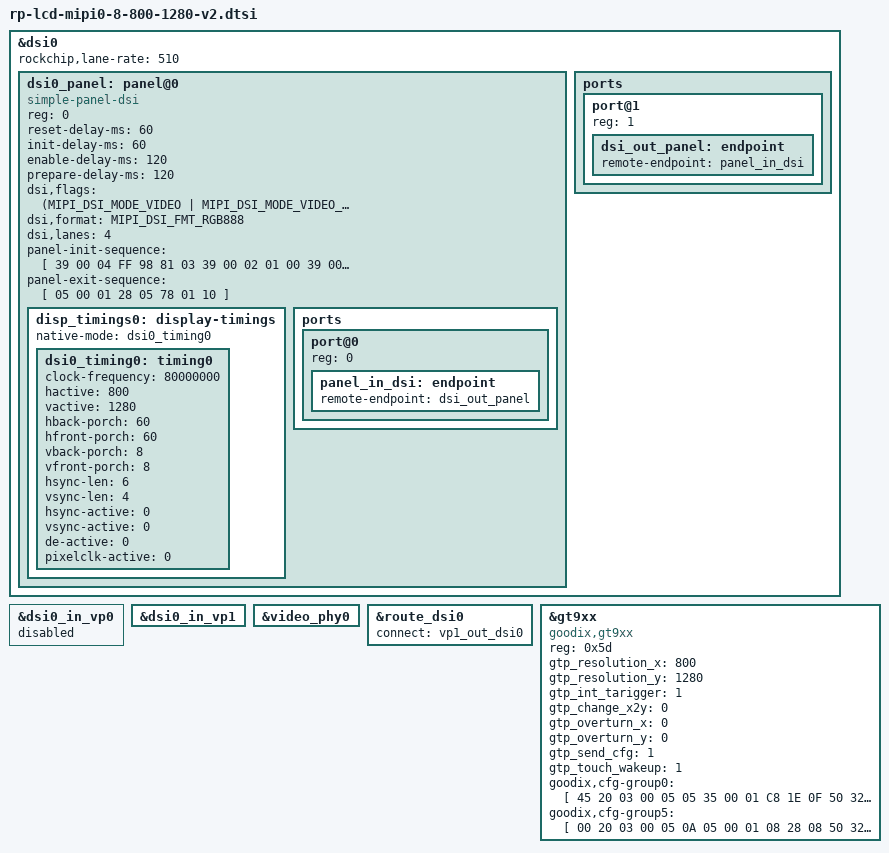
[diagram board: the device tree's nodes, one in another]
#include "rp-lcd-hdmi.dtsi"
#define RP_SINGLE_LCD





&dsi0 {
	status = "okay";
	rockchip,lane-rate = <510>;
	dsi0_panel: panel@0 {
		status = "okay";
		compatible = "simple-panel-dsi";
		reg = <0>;
                reset-delay-ms = <60>;
                init-delay-ms = <60>;
                enable-delay-ms = <120>;
                prepare-delay-ms = <120>;
                dsi,flags = <(MIPI_DSI_MODE_VIDEO | MIPI_DSI_MODE_VIDEO_BURST |
                                MIPI_DSI_MODE_LPM | MIPI_DSI_MODE_EOT_PACKET)>;
		dsi,format = <MIPI_DSI_FMT_RGB888>;
		dsi,lanes  = <4>;
		
		/**
		 * power-supply = <>;
		 * reset-gpios = <>;
		 *
		 * lcd reset pin and power supply
		 * please refer to ***-lcd-gpio.dtsi
		 * that included in main dts.
		 */
		
		panel-init-sequence = [
			39 00 04 FF 98 81 03
			39 00 02 01 00
			39 00 02 02 00
			39 00 02 03 73
			39 00 02 04 D7
			39 00 02 05 00
			39 00 02 06 08
			39 00 02 07 11
			39 00 02 08 00
			39 00 02 09 3F
			39 00 02 0a 00
			39 00 02 0b 00
			39 00 02 0c 00
			39 00 02 0d 00
			39 00 02 0e 00
			39 00 02 0f 3F
			39 00 02 10 3F
			39 00 02 11 00
			39 00 02 12 00
			39 00 02 13 00
			39 00 02 14 00
			39 00 02 15 00
			39 00 02 16 00
			39 00 02 17 00
			39 00 02 18 00
			39 00 02 19 00
			39 00 02 1a 00
			39 00 02 1b 00
			39 00 02 1c 00
			39 00 02 1d 00
			39 00 02 1e 40
			39 00 02 1f 80
			39 00 02 20 06
			39 00 02 21 01
			39 00 02 22 00
			39 00 02 23 00
			39 00 02 24 00
			39 00 02 25 00
			39 00 02 26 00
			39 00 02 27 00
			39 00 02 28 33
			39 00 02 29 33
			39 00 02 2a 00
			39 00 02 2b 00
			39 00 02 2c 00
			39 00 02 2d 00
			39 00 02 2e 00
			39 00 02 2f 00
			39 00 02 30 00
			39 00 02 31 00
			39 00 02 32 00
			39 00 02 33 00
			39 00 02 34 00
			39 00 02 35 00
			39 00 02 36 00
			39 00 02 37 00
			39 00 02 38 00
			39 00 02 39 00
			39 00 02 3a 00
			39 00 02 3b 00
			39 00 02 3c 00
			39 00 02 3d 00
			39 00 02 3e 00
			39 00 02 3f 00
			39 00 02 40 00
			39 00 02 41 00
			39 00 02 42 00
			39 00 02 43 00
			39 00 02 44 00
			39 00 02 50 01
			39 00 02 51 23
			39 00 02 52 44
			39 00 02 53 67
			39 00 02 54 89
			39 00 02 55 ab
			39 00 02 56 01
			39 00 02 57 23
			39 00 02 58 45
			39 00 02 59 67
			39 00 02 5a 89
			39 00 02 5b ab
			39 00 02 5c cd
			39 00 02 5d ef
			39 00 02 5e 00
			39 00 02 5f 0C
			39 00 02 60 0C
			39 00 02 61 0F
			39 00 02 62 0F
			39 00 02 63 0E
			39 00 02 64 0E
			39 00 02 65 06
			39 00 02 66 07
			39 00 02 67 0D
			39 00 02 68 02
			39 00 02 69 02
			39 00 02 6a 02
			39 00 02 6b 02
			39 00 02 6c 02
			39 00 02 6d 02
			39 00 02 6e 0D
			39 00 02 6f 02
			39 00 02 70 02
			39 00 02 71 05
			39 00 02 72 01
			39 00 02 73 08
			39 00 02 74 00
			39 00 02 75 0C
			39 00 02 76 0C
			39 00 02 77 0F
			39 00 02 78 0F
			39 00 02 79 0E
			39 00 02 7a 0E
			39 00 02 7b 06
			39 00 02 7c 07
			39 00 02 7d 0D
			39 00 02 7e 02
			39 00 02 7f 02
			39 00 02 80 02
			39 00 02 81 02
			39 00 02 82 02
			39 00 02 83 02
			39 00 02 84 0D
			39 00 02 85 02
			39 00 02 86 02
			39 00 02 87 05
			39 00 02 88 01
			39 00 02 89 08
			39 00 02 8A 00
			
			39 00 04 FF 98 81 04
			39 00 02 6E 3B
			39 00 02 6F 57
			39 00 02 3A 24
			39 00 02 8D 1F
			39 00 02 87 BA
			39 00 02 B2 D1
			39 00 02 88 0B
			39 00 02 38 01
			39 00 02 39 00
			39 00 02 B5 07
			39 00 02 31 75
			39 00 02 3B 98
			
			39 00 04 FF 98 81 01
			39 00 02 22 0A
			39 00 02 31 09
			39 00 02 35 07
			39 00 02 53 7B
			39 00 02 55 40
			39 00 02 50 86
			39 00 02 51 82
			39 00 02 60 27
			39 00 02 62 20
			39 00 02 A0 00
			39 00 02 A1 12
			39 00 02 A2 20
			39 00 02 A3 13
			39 00 02 A4 14
			39 00 02 A5 27
			39 00 02 A6 1D
			39 00 02 A7 1F
			39 00 02 A8 7C
			39 00 02 A9 1D
			39 00 02 AA 2A
			39 00 02 AB 6B
			39 00 02 AC 1A
			39 00 02 AD 18
			39 00 02 AE 4E
			39 00 02 AF 24
			39 00 02 B0 2A
			39 00 02 B1 4D
			39 00 02 B2 5B
			39 00 02 B3 23
			39 00 02 C0 00
			39 00 02 C1 13
			39 00 02 C2 20
			39 00 02 C3 12
			39 00 02 C4 15
			39 00 02 C5 28
			39 00 02 C6 1C
			39 00 02 C7 1E
			39 00 02 C8 7B
			39 00 02 C9 1E
			39 00 02 CA 29
			39 00 02 CB 6C
			39 00 02 CC 1A
			39 00 02 CD 19
			39 00 02 CE 4D
			39 00 02 CF 22
			39 00 02 D0 2A
			39 00 02 D1 4D
			39 00 02 D2 5B
			39 00 02 D3 23		
			39 00 04 FF 98 81 00
			
			05 78 01 11
			05 78 01 29
		];
		
		panel-exit-sequence = [
			05 00 01 28
			05 78 01 10
		];

		disp_timings0: display-timings {
			native-mode = <&dsi0_timing0>;
			dsi0_timing0: timing0 {
				clock-frequency = <80000000>;
                                hactive = <800>;
                                vactive = <1280>;
                                hback-porch = <60>;
                                hfront-porch = <60>;
                                vback-porch = <8>;
                                vfront-porch = <8>;
                                hsync-len = <6>;
                                vsync-len = <4>;
                                hsync-active = <0>;
                                vsync-active = <0>;
                                de-active = <0>;
                                pixelclk-active = <0>;
			};
		};

		ports {
			#address-cells = <1>;
			#size-cells = <0>;

			port@0 {
				reg = <0>;
				panel_in_dsi: endpoint {
					remote-endpoint = <&dsi_out_panel>;
				};
			};
		};
	};

	ports {
		#address-cells = <1>;
		#size-cells = <0>;

		port@1 {
			reg = <1>;
			dsi_out_panel: endpoint {
				remote-endpoint = <&panel_in_dsi>;
			};
		};
	};

};




&dsi0_in_vp0 {
	status = "disabled";
};

&dsi0_in_vp1 {
	status = "okay";
};



&video_phy0 {
	status = "okay";
};


&route_dsi0 {
	status = "okay";
	connect = <&vp1_out_dsi0>;
};



&gt9xx {
	status = "okay";
	compatible = "goodix,gt9xx";
	reg = <0x5d>;
	gtp_resolution_x = <800>;
	gtp_resolution_y = <1280>;
	gtp_int_tarigger = <1>;
	gtp_change_x2y = <0>;
	gtp_overturn_x = <0>;
	gtp_overturn_y = <0>;
	gtp_send_cfg = <1>;
	gtp_touch_wakeup = <1>;

	/**
	 * goodix_rst_gpio = <>;
	 * goodix_irq_gpio = <>;
	 *
	 * touch panel interrupt and reset pin
	 * please refer to ***-lcd-gpio.dtsi
	 * that included in main dts.
	 */

	goodix,cfg-group0 = [
		45 20 03 00 05 05 35 00 01 C8 
		1E 0F 50 32 03 05 00 00 00 00 
		00 00 04 18 1A 1E 14 8C 2E 0E 
		1E 20 EB 04 00 00 00 BA 02 2D 
		00 00 00 00 00 03 00 00 00 00 
		00 0F 2D 94 D5 02 07 00 00 04 
		E6 10 00 BB 14 00 92 1A 00 78 
		20 00 61 28 00 61 00 00 00 00 
		00 00 00 00 00 00 00 00 00 00 
		00 00 00 00 00 00 00 00 00 00 
		00 00 00 00 00 00 00 00 00 00 
		00 00 1C 1A 18 16 14 12 10 0E 
		0C 0A 08 06 04 02 00 00 00 00 
		00 00 00 00 00 00 00 00 00 00 
		00 00 2A 29 28 26 24 22 21 20 
		1F 1E 1D 1C 18 16 00 02 04 06 
		08 0A 0C 0F 10 12 13 14 00 00 
		00 00 00 00 00 00 00 00 00 00 
		00 00 00 00 CB 01
	];
		
	goodix,cfg-group5 = [
    00 20 03 00 05 0A 05 00 01 08 28 08 
					50 32 03 05 00 00 00 00 00 00 00 18 
					1A 1E 14 8C 2C 0E 17 15 31 0D 00 00 
					02 9B 04 1D 00 00 00 00 00 03 64 32 
					00 00 00 11 25 94 C5 02 07 00 00 04 
					60 12 00 5D 15 00 57 19 00 54 1D 00 
					4F 22 00 4F 00 00 00 00 00 00 00 00 
					00 00 00 00 00 00 00 00 00 00 00 00 
					00 00 00 00 00 00 00 00 00 00 00 00 
					00 00 00 00 1C 1A 18 16 14 12 10 0E 
					0C 0A 08 06 04 02 00 00 00 00 00 00 
					00 00 00 00 00 00 00 00 00 00 28 26 
					24 22 21 20 1F 1E 1D 1C 18 16 14 13 
					00 02 04 06 08 0A 0C 0F 10 12 FF FF 
					00 00 00 00 00 00 00 00 00 00 00 00 
					00 00 00 00 2F 01];	
};
